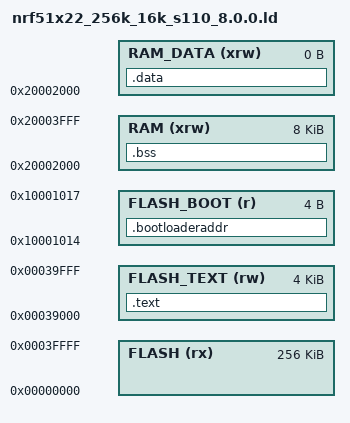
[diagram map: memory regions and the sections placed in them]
/*
    GNU linker script for NRF51822 AA w/ S110 8.0.0 SoftDevice
*/
/* Specify the memory areas */
SEARCH_DIR(.)
GROUP(-lgcc -lc -lnosys)
MEMORY
{
    FLASH (rx)      : ORIGIN = 0x00000000, LENGTH = 0x040000 /* entire flash, 256 KiB */
    FLASH_TEXT (rw) : ORIGIN = 0x00039000, LENGTH = 0x001000 /* 4 KiB */
    FLASH_BOOT (r)  : ORIGIN = 0x10001014, LENGTH = 4        /* 4 bytes */
    RAM (xrw)       : ORIGIN = 0x20002000, LENGTH = 0x002000 /* 8 KiB */
    RAM_DATA (xrw)  : ORIGIN = 0x20002000, LENGTH = 0        /* empty to disallow .data */
}

/* top end of the stack */

/*_stack_end = ORIGIN(RAM) + LENGTH(RAM);*/
_estack = ORIGIN(RAM) + LENGTH(RAM);

/* RAM extents for the garbage collector */
_ram_end = ORIGIN(RAM) + LENGTH(RAM);

/* define output sections */
SECTIONS
{
    .bootloaderaddr :
    {
        LONG(_stext);
    } >FLASH_BOOT

    /* The program code and other data goes into FLASH */
    .text :
    {
        _stext = .;
        . = ALIGN(4);
        KEEP(*(.isr_vector))
        *(.text)           /* .text sections (code) */
        *(.text*)          /* .text* sections (code) */
        *(.rodata)         /* .rodata sections (constants, strings, etc.) */
        *(.rodata*)        /* .rodata* sections (constants, strings, etc.) */
        . = ALIGN(4);
        _etext = .;        /* define a global symbol at end of code */
    } >FLASH_TEXT


    /* used by the startup to initialize data */
    _sidata = .;

    /* This is the initialized data section
    The program executes knowing that the data is in the RAM
    but the loader puts the initial values in the FLASH (inidata).
    It is one task of the startup to copy the initial values from FLASH to RAM. */
    .data : AT (_sidata)
    {
        . = ALIGN(4);
        _sdata = .;        /* create a global symbol at data start; used by startup code in order to initialise the .data section in RAM */
        _ram_start = .;    /* create a global symbol at ram start for garbage collector */
        *(.data)           /* .data sections */
        *(.data*)          /* .data* sections */

        . = ALIGN(4);
        _edata = .;        /* define a global symbol at data end; used by startup code in order to initialise the .data section in RAM */
    } >RAM_DATA

    /* Uninitialized data section */
    .bss :
    {
        . = ALIGN(4);
        _sbss = .;         /* define a global symbol at bss start; used by startup code */
        *(.bss)
        *(.bss*)
        *(COMMON)

        . = ALIGN(4);
        _ebss = .;         /* define a global symbol at bss end; used by startup code and GC */
    } >RAM

    .ARM.attributes 0 : { *(.ARM.attributes) }
}
